# FRCTL_367.0 register map
Vendor: Texas Instruments
Peripheral module from a debugger description file (folder msp430).
Registers are 16-bit, read-write, no defined reset value unless marked. A register's access mark holds for its fields unless they carry their own. Offsets are as the file gives them; lines under a group give offsets from that group; [hi:lo] are bit positions; {n}, {i} and the like mark numbered series; 'fields as' and 'values as' point back to an identical list; <NAME> marks a mode.

## FRCTL
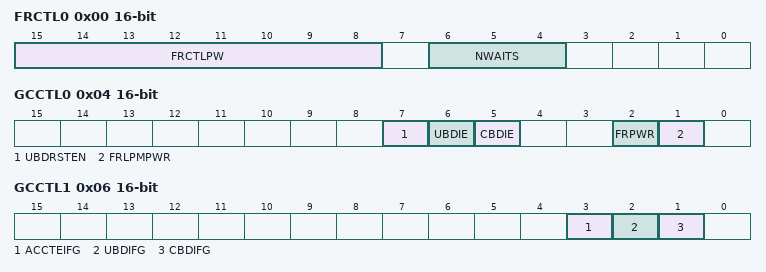
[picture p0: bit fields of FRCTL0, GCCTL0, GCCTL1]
0x00 FRCTL0 — FRAM Controller Control Register 0
  [15:8] FRCTLPW — FRCTLPW password
  [6:4] NWAITS — Wait state numbers
    {v}=FRAM wait states: {v} (v=0..7)
0x04 GCCTL0 — General Control Register 0
  [7] UBDRSTEN — Enable Power Up Clear (PUC) reset for the uncorrectable bit error detection flag (UBDIFG)
    0=PUC not initiated on uncorrectable bit error detection flag; 1=PUC initiated on uncorrectable bit error detection flag. Generates vector in SYSRSTIV. Clear the UBDIE bit.
  [6] UBDIE — Enable NMI event for the uncorrectable bit error detection flag (UBDIFG)
    0=Disable NMI for the uncorrectable bit error detection flag (UBDIFG); 1=Enable NMI for the uncorrectable bit error detection flag (UBDIFG). Generates vector in SYSSNIV. Clear the UBDRSTEN bit.
  [5] CBDIE — Enable NMI event for the correctable bit error detection flag (CBDIFG)
    0=Disable NMI for the correctable bit error detection flag (CBDIFG); 1=Disable NMI for the correctable bit error detection flag (CBDIFG). Generates vector in SYSSNIV.
  [2] FRPWR — FRAM Memory Power Control Request
    0=Enable INACTIVE mode; 1=Enable ACTIVE mode
  [1] FRLPMPWR — Enables FRAM auto power up after LPM
    0=FRAM startup is delayed to the first FRAM access after exit from LPM; 1=FRAM is powered up immediately on exit from LPM
0x06 GCCTL1 — General Control Register 1
  [3] ACCTEIFG — Access time error flag
    0=No interrupt pending; 1=Interrupt pending. Can be cleared by writing '0' or by reading SYSSNIV when it is the highest pending interrupt.
  [2] UBDIFG — FRAM uncorrectable bit error detection flag
    values as ACCTEIFG
  [1] CBDIFG — FRAM correctable bit error detection flag
    0=No interrupt is pending; 1=Interrupt pending. Can be cleared by writing '0' or by reading SYSSNIV if it is the highest pending interrupt.
